# STM32C051 register map
File version: 1.2
CPU: CM0+ r0p0, little endian, MPU, no FPU, 4 interrupt priority bits
Registers are 32-bit, read-write, reset 0x0 unless marked. A register's access mark holds for its fields unless they carry their own. Offsets are from the block's base; [hi:lo] are bit positions; {n}, {i} and the like mark numbered series; 'fields as' and 'values as' point back to an identical list; <NAME> marks a mode.

## SYSCFG — Spider_SYSCFG register block
Base 0x40010000
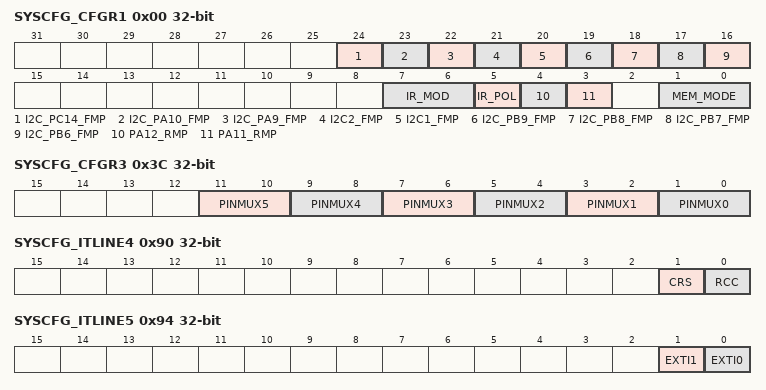
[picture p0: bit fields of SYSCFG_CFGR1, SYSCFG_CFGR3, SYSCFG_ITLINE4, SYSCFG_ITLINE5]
0x00 SYSCFG_CFGR1 (reset mask 0xFFFFFFF0) — SYSCFG configuration register 1
  [24] I2C_PC14_FMP — Fast Mode Plus (FM+) enable for PC14 This bit is set and cleared by software. It enables I<sup>2</sup>C FM+ driving capability on PC14 I/O port. Note: Not available on STM32C011xx.
    0=Disable if not enabled through I2Cx_FMP; 1=Enable
  [23] I2C_PA10_FMP — Fast Mode Plus (FM+) enable for PA10 This bit is set and cleared by software. It enables I<sup>2</sup>C FM+ driving capability on PA10 I/O port.
    0=Disable disabled if not enabled through I2Cx_FMP; 1=Enable
  [22] I2C_PA9_FMP — Fast Mode Plus (FM+) enable for PA9 This bit is set and cleared by software. It enables I<sup>2</sup>C FM+ driving capability on PA9 I/O port.
    0=Disable disabled if not enabled through I2Cx_FMP; 1=Enable
  [21] I2C2_FMP — Fast Mode Plus (FM+) enable for I2C2 This bit is set and cleared by software. It enables I<sup>2</sup>C FM+ driving capability on I/O ports configured as I2C2 through GPIOx_AFR registers. Note: Only applicable to STM32C071xx. Reserved on the other products.
    0=Disable disabled if not enabled through I2C_y_FMP; 1=Enable
  [20] I2C1_FMP — Fast Mode Plus (FM+) enable for I2C1 This bit is set and cleared by software. It enables I<sup>2</sup>C FM+ driving capability on I/O ports configured as I2C1 through GPIOx_AFR registers.
    values as I2C2_FMP
  [19] I2C_PB9_FMP — Fast Mode Plus (FM+) enable for PB9 This bit is set and cleared by software. It enables I<sup>2</sup>C FM+ driving capability on PB9 I/O port. Note: Not available on STM32C011xx.
    0=Disable disabled if not enabled through I2Cx_FMP; 1=Enable
  [18] I2C_PB8_FMP — Fast Mode Plus (FM+) enable for PB8 This bit is set and cleared by software. It enables I<sup>2</sup>C FM+ driving capability on PB8 I/O port. Note: Not available on STM32C011xx.
    0=Disable disabled if not enabled through I2Cx_FMP; 1=Enable
  [17] I2C_PB7_FMP — Fast Mode Plus (FM+) enable for PB7 This bit is set and cleared by software. It enables I<sup>2</sup>C FM+ driving capability on PB7 I/O port.
    0=Disable disabled if not enabled through I2Cx_FMP; 1=Enable
  [16] I2C_PB6_FMP — Fast Mode Plus (FM+) enable for PB6 This bit is set and cleared by software. It enables I<sup>2</sup>C FM+ driving capability on PB6 I/O port.
    0=Disable disabled if not enabled through I2Cx_FMP; 1=Enable
  [7:6] IR_MOD — IR Modulation Envelope signal selection This bitfield selects the signal for IR modulation envelope:
    0=TIM16; 1=USART1; 2=USART2
  [5] IR_POL — IR output polarity selection
    0=Output of IRTIM (IR_OUT) is not inverted; 1=Output of IRTIM (IR_OUT) is inverted
  [4] PA12_RMP — PA12 pin remapping This bit is set and cleared by software. When set, it remaps the PA12 pin to operate as PA10 GPIO port, instead as PA12 GPIO port. Note: If the PINMUX4[1:0] bitfield of the SYSCFG_CFGR3 register is at 00, PA12_RMP must be kept at 0 to prevent conflict due to two GPIO outputs with different output levels connected to the same pin.
    0=No remap (PA12); 1=Remap (PA10)
  [3] PA11_RMP — PA11 pin remapping This bit is set and cleared by software. When set, it remaps the PA11 pin to operate as PA9 GPIO port, instead as PA11 GPIO port. Note: If the PINMUX2[1:0] bitfield of the SYSCFG_CFGR3 register is at 00, PA11_RMP must be kept at 0 to prevent conflict due to two GPIO outputs with different output levels connected to the same pin.
    0=No remap (PA11); 1=Remap (PA9)
  [1:0] MEM_MODE — Memory mapping selection bits This bitfield controlled by software selects the memory internally mapped at the address 0x0000 0000. Its reset value is determined by the boot mode configuration. Refer to Section 3: Boot configuration for more details. x0: Main Flash memory
    1=System Flash memory; 3=Embedded SRAM
0x18 SYSCFG_CFGR2 reset not defined — SYSCFG configuration register 2
  [0] LOCKUP_LOCK — Cortex<Superscript> <Default Font>-M0+ LOCKUP enable This bit is set by software and cleared by system reset. When set, it enables the connection of Cortex<Superscript> <Default Font>-M0+ LOCKUP (HardFault) output to the TIM1/16/17 Break input.
    0=Disable; 1=Enable
0x3C SYSCFG_CFGR3 reset not defined — SYSCFG configuration register 3
  [11:10] PINMUX5 — Pin GPIO multiplexer 5 This bit is set by software and cleared by system reset. It assigns a GPIO to a pin.
    {v}=B_{0x0+v}_STM32C011X___GPIO_ASSIGNED_TO_WLCSP12_PIN_F1 (PA{v+3}) (v=0..3)
  [9:8] PINMUX4 — Pin GPIO multiplexer 4 This bit is set by software and cleared by system reset. It assigns a GPIO to a pin. 1x: Reserved Note: The PA12_RMP bit of the SYSCFG_CFGR1 takes priority over the selection through this bitfield. Refer to the description of the SYSCFG_CFGR1 register for more details.
    0=B_0x0_STM32C011X___GPIO_ASSIGNED_TO_WLCSP12_PIN_E2 (PA7); 1=B_0x1_STM32C011X___GPIO_ASSIGNED_TO_WLCSP12_PIN_E2 (PA12)
  [7:6] PINMUX3 — Pin GPIO multiplexer 3 This bit is set by software and cleared by system reset. It assigns a GPIO to a pin. 1x: Reserved
    0=B_0x0_STM32C011X___GPIO_ASSIGNED_TO_SO8_PIN_8 (PA14); 1=B_0x1_STM32C011X___GPIO_ASSIGNED_TO_SO8_PIN_8 (PB6); 2=B_0x2_STM32C011X___GPIO_ASSIGNED_TO_SO8_PIN_8 (PC15)
  [5:4] PINMUX2 — Pin GPIO multiplexer 2 This bit is set by software and cleared by system reset. It assigns a GPIO to a pin. 1x: Reserved Note: The PA11_RMP bit of the SYSCFG_CFGR1 takes priority over the selection through this bitfield. Refer to the description of the SYSCFG_CFGR1 register for more details.
    0=B_0x0_STM32C011X___GPIO_ASSIGNED_TO_SO8_PIN_5 (PA8); 1=B_0x1_STM32C011X___GPIO_ASSIGNED_TO_SO8_PIN_5 (PA11)
  [3:2] PINMUX1 — Pin GPIO multiplexer 1 This bit is set by software and cleared by system reset. It assigns a GPIO to a pin. 1x: Reserved
    0=B_0x0_STM32C011X___GPIO_ASSIGNED_TO_SO8_PIN_4 (PF2); 1=B_0x1_STM32C011X___GPIO_ASSIGNED_TO_SO8_PIN_4 (PA0); 2=B_0x2_STM32C011X___GPIO_ASSIGNED_TO_SO8_PIN_4 (PA1); 3=B_0x3_STM32C011X___GPIO_ASSIGNED_TO_SO8_PIN_4 (PA2)
  [1:0] PINMUX0 — Pin GPIO multiplexer 0 This bit is set by software and cleared by system reset. It assigns a GPIO to a pin. 1x: Reserved 1x: Reserved
    0=B_0x0_STM32C011X___GPIO_ASSIGNED_TO_SO8_PIN_1 (PB7)
0x80 SYSCFG_ITLINE0 ro reset not defined — SYSCFG interrupt line 0 status register
  [0] WWDG — Window watchdog interrupt pending flag
0x84 SYSCFG_ITLINE1 ro reset not defined — SYSCFG interrupt line 1 status register
  [1] PVM_VDDIO2_OUT — V<sub>DDIO2</sub> supply monitoring interrupt request pending (EXTI line 34)
0x88 SYSCFG_ITLINE2 ro reset not defined — SYSCFG interrupt line 2 status register
  [1] RTC — RTC interrupt request pending (EXTI line 19)
0x8C SYSCFG_ITLINE3 ro reset not defined — SYSCFG interrupt line 3 status register
  [1] FLASH_ITF — Flash interface interrupt request pending
0x90 SYSCFG_ITLINE4 ro reset not defined — SYSCFG interrupt line 4 status register
  [1] CRS — CRS interrupt request pending Note: Only applicable on STM32C071xx, reserved on other products.
  [0] RCC — Reset and clock control interrupt request pending
0x94 SYSCFG_ITLINE5 ro reset not defined — SYSCFG interrupt line 5 status register
  [1] EXTI1 — EXTI line 1 interrupt request pending
  [0] EXTI0 — EXTI line 0 interrupt request pending
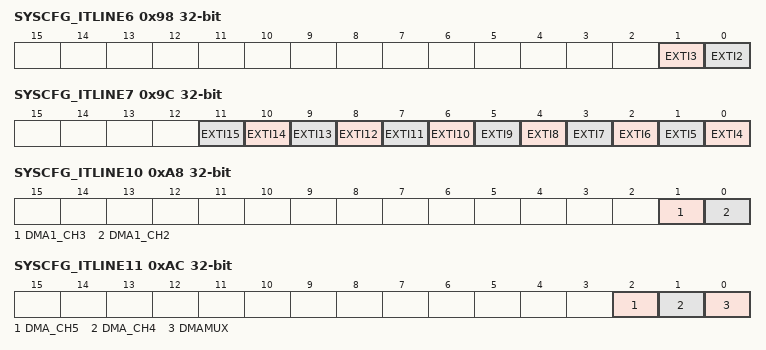
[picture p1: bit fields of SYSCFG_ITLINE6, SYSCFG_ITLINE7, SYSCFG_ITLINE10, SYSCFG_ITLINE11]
0x98 SYSCFG_ITLINE6 ro reset not defined — SYSCFG interrupt line 6 status register
  [1] EXTI3 — EXTI line 3 interrupt request pending
  [0] EXTI2 — EXTI line 2 interrupt request pending
0x9C SYSCFG_ITLINE7 ro reset not defined — SYSCFG interrupt line 7 status register
  [n-4] EXTI{n} (n=4..15) — EXTI line {n} interrupt request pending
0xA0 SYSCFG_ITLINE8 ro reset not defined — SYSCFG interrupt line 8 status register
  [0] USB — USB interrupt request pending
0xA4 SYSCFG_ITLINE9 ro reset not defined — SYSCFG interrupt line 9 status register
  [0] DMA1_CH1 — DMA1 channel 1interrupt request pending
0xA8 SYSCFG_ITLINE10 ro reset not defined — SYSCFG interrupt line 10 status register
  [1] DMA1_CH3 — DMA1 channel 3 interrupt request pending
  [0] DMA1_CH2 — DMA1 channel 2 interrupt request pending
0xAC SYSCFG_ITLINE11 ro reset not defined — SYSCFG interrupt line 11 status register
  [2] DMA_CH5 — DMA channel 5 interrupt request pending Note: Only applicable on STM32C071xx, reserved on the other products.
  [1] DMA_CH4 — DMA channel 5 interrupt request pending Note: Only applicable on STM32C071xx, reserved on the other products.
  [0] DMAMUX — DMAMUX interrupt request pending
0xB0 SYSCFG_ITLINE12 ro reset not defined — SYSCFG interrupt line 12 status register
  [0] ADC — ADC interrupt request pending
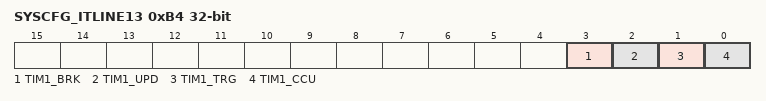
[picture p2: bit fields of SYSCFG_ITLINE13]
0xB4 SYSCFG_ITLINE13 ro reset not defined — SYSCFG interrupt line 13 status register
  [3] TIM1_BRK — Timer 1 break interrupt request pending
  [2] TIM1_UPD — Timer 1 update interrupt request pending
  [1] TIM1_TRG — Timer 1 trigger interrupt request pending
  [0] TIM1_CCU — Timer 1 commutation interrupt request pending
0xB8 SYSCFG_ITLINE14 ro reset not defined — SYSCFG interrupt line 14 status register
  [0] TIM1_CC — Timer 1 capture compare interrupt request pending
0xBC SYSCFG_ITLINE15 ro reset not defined — SYSCFG interrupt line 15 status register
  [0] TIM2 — TIM2 interrupt request pending
0xC0 SYSCFG_ITLINE16 ro reset not defined — SYSCFG interrupt line 16 status register
  [0] TIM3 — Timer 3 interrupt request pending
0xCC SYSCFG_ITLINE19 ro reset not defined — SYSCFG interrupt line 19 status register
  [0] TIM14 — Timer 14 interrupt request pending
0xD4 SYSCFG_ITLINE21 ro reset not defined — SYSCFG interrupt line 21 status register
  [0] TIM16 — Timer 16 interrupt request pending
0xD8 SYSCFG_ITLINE22 ro reset not defined — SYSCFG interrupt line 22 status register
  [0] TIM17 — Timer 17 interrupt request pending
0xDC SYSCFG_ITLINE23 ro reset not defined — SYSCFG interrupt line 23 status register
  [0] I2C1 — I2C1 interrupt request pending, combined with EXTI line 23
0xE0 SYSCFG_ITLINE24 ro reset not defined — SYSCFG interrupt line 24 status register
  [0] I2C2 — I2C2 interrupt request pending
0xE4 SYSCFG_ITLINE25 ro reset not defined — SYSCFG interrupt line 25 status register
  [0] SPI1 — SPI1 interrupt request pending
0xE8 SYSCFG_ITLINE26 ro reset not defined — SYSCFG interrupt line 26 status register
  [0] SPI2 — SPI2 interrupt request pending
0xEC SYSCFG_ITLINE27 ro reset not defined — SYSCFG interrupt line 27 status register
  [0] USART1 — USART1 interrupt request pending, combined with EXTI line 25
0xF0 SYSCFG_ITLINE28 ro — SYSCFG interrupt line 28 status register
  [0] USART2 — USART2 interrupt request pending (EXTI line 26)
